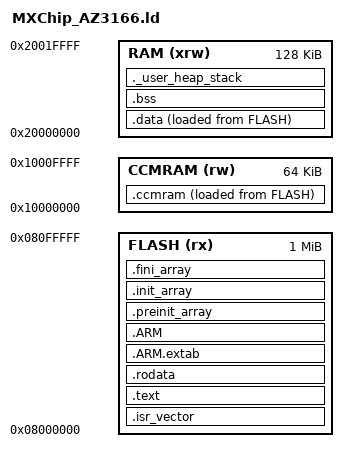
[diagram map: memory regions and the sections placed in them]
/* Entry Point */
ENTRY(Reset_Handler)

/* _Heap_Size = 0x7000;	/* required amount of heap  */
/* _Stack_Size = 0x1000;	/* required amount of stack */

_estack = 0x20000000 + 128K - 1;
_Min_Heap_Size = 0;
_Min_Stack_Size = 0x200;

/* Memories definition */
MEMORY
{
  RAM    (xrw)   : ORIGIN = 0x20000000,   LENGTH = 128K
  FLASH   (rx)   : ORIGIN = 0x8000000,    LENGTH = 1024K
  CCMRAM (rw)    : ORIGIN = 0x10000000,   LENGTH = 64K
}

/* Sections */
SECTIONS
{
  /* The startup code into "FLASH" Rom type memory */
  .isr_vector :
  {
    . = ALIGN(4);
    KEEP(*(.isr_vector)) /* Startup code */
    . = ALIGN(4);
  } >FLASH

  /* The program code and other data into "FLASH" Rom type memory */
  .text :
  {
    . = ALIGN(4);
    *(.text)           /* .text sections (code) */
    *(.text*)          /* .text* sections (code) */
    *(.glue_7)         /* glue arm to thumb code */
    *(.glue_7t)        /* glue thumb to arm code */
    *(.eh_frame)

    KEEP (*(.init))
    KEEP (*(.fini))

    . = ALIGN(4);
    _etext = .;        /* define a global symbols at end of code */
  } >FLASH

  /* Constant data into "FLASH" Rom type memory */
  .rodata :
  {
    . = ALIGN(4);
    *(.rodata)         /* .rodata sections (constants, strings, etc.) */
    *(.rodata*)        /* .rodata* sections (constants, strings, etc.) */
    . = ALIGN(4);
  } >FLASH

  .ARM.extab   : { 
    . = ALIGN(4);
    *(.ARM.extab* .gnu.linkonce.armextab.*)
    . = ALIGN(4);
  } >FLASH
  
  .ARM : {
    . = ALIGN(4);
    __exidx_start = .;
    *(.ARM.exidx*)
    __exidx_end = .;
    . = ALIGN(4);
  } >FLASH

  .preinit_array     :
  {
    . = ALIGN(4);
    PROVIDE_HIDDEN (__preinit_array_start = .);
    KEEP (*(.preinit_array*))
    PROVIDE_HIDDEN (__preinit_array_end = .);
    . = ALIGN(4);
  } >FLASH
  
  .init_array :
  {
    . = ALIGN(4);
    PROVIDE_HIDDEN (__init_array_start = .);
    KEEP (*(SORT(.init_array.*)))
    KEEP (*(.init_array*))
    PROVIDE_HIDDEN (__init_array_end = .);
    . = ALIGN(4);
  } >FLASH
  
  .fini_array :
  {
    . = ALIGN(4);
    PROVIDE_HIDDEN (__fini_array_start = .);
    KEEP (*(SORT(.fini_array.*)))
    KEEP (*(.fini_array*))
    PROVIDE_HIDDEN (__fini_array_end = .);
    . = ALIGN(4);
  } >FLASH

  /* Used by the startup to initialize data */
  _sidata = LOADADDR(.data);

  /* Initialized data sections into "RAM" Ram type memory */
  .data : 
  {
    . = ALIGN(4);
    _sdata = .;        /* create a global symbol at data start */
    *(.data)           /* .data sections */
    *(.data*)          /* .data* sections */

    . = ALIGN(4);
    _edata = .;        /* define a global symbol at data end */
    
  } >RAM AT> FLASH

  _siccmram = LOADADDR(.ccmram);
  .ccmram :
  { 
    . = ALIGN(4);
    _sccmram = .;
    *(.ccmram)
    *(.ccmram*)
    . = ALIGN(4);
    _eccmram = .;
  } >CCMRAM AT> FLASH

  /* Uninitialized data section into "RAM" Ram type memory */
  . = ALIGN(4);
  .bss :
  {
    /* This is used by the startup in order to initialize the .bss section */
    _sbss = .;         /* define a global symbol at bss start */
    __bss_start__ = _sbss;
    *(.bss)
    *(.bss*)
    *(COMMON)

    . = ALIGN(4);
    _ebss = .;         /* define a global symbol at bss end */
    __bss_end__ = _ebss;
  } >RAM

  /* User_heap and stack sections */
  ._user_heap_stack :
  {
    . = ALIGN(8);
    PROVIDE ( end = . );
    PROVIDE ( _end = . );
    . = . + _Min_Heap_Size;
    . = . + _Min_Stack_Size;
    . = ALIGN(8);
    __RAM_segment_used_end__ = .;      /* For ThreadX */
  } >RAM

  /* User_heap and stack sections, used to check that there is enough "RAM2" Ram  type memory left 
  .heap :
  {
    . = ALIGN(8);
    PROVIDE ( end = . );
    _sheap = .;
    . = . + _Heap_Size;
    . = ALIGN(8);
    _eheap = .;
  } >RAM2

  .stack :
  {
    . = ALIGN(8);
    _estack = .;
    . = . + _Stack_Size;
    . = ALIGN(8);
    _sstack = .;
  } >RAM2
*/
  /* Remove information from the compiler libraries */
  /DISCARD/ :
  {
    libc.a ( * )
    libm.a ( * )
    libgcc.a ( * )
  }

  .ARM.attributes 0 : { *(.ARM.attributes) }
}

/* Set the RAM segment used end for threadx */
PROVIDE( __RAM_segment_used_end__ = 0 );
